# alias_remap_wrap: IP-XACT component
VLNV tenstorrent.com:ocah:alias_remap_wrap:1.0

## Address spaces and blocks
alias_remap_wrap_mmap.alias_remap_wrap: base 'h0, range 'h100, width 64

## Registers
Registers are 64-bit, read-write, reset 0x0 unless marked. A register's access mark holds for its fields unless they carry their own. Offsets are from the block's base; lines under a group give offsets from that group; [hi:lo] are bit positions; {n}, {i} and the like mark numbered series; 'fields as' and 'values as' point back to an identical list; <NAME> marks a mode.

## alias_remap_wrap_mmap.alias_remap_wrap — Wrapper address map instantiating one alias remap register block per remap region.
Base 0x00000000
{0x0+0x20*i} alias_remap[{i}] (i=0..7) group — TLB Registers for address remapping and attribute tagging
  0x00 REGION group
    0x00 region_start
      [55:12] start_addr — Start of remap region
    0x08 region_end
      [55:12] end_addr — End of remap region (non-inclusive). A region whose end is at or below its start contains no address and never remaps.
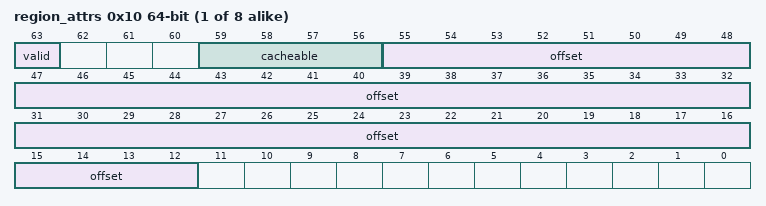
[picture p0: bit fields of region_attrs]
    0x10 region_attrs
      [63] valid — If set, this remap will be active
      [59:56] cacheable — Set to change the value of the axcache field of the transaction. This field will override all existing axcache bits.
      [55:12] offset — The value of this field is added to bits [55:12] of the input address when it falls within the remap region. The addition is modulo 2^44, so a carry out of bit 55 is discarded. The lower 12 bits of the address are preserved unchanged. When more than one valid region contains the address, the lowest-numbered region applies.

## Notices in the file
SPDX-License-Identifier: Apache-2.0
SPDX-FileCopyrightText: 2026 Tenstorrent USA, Inc.
